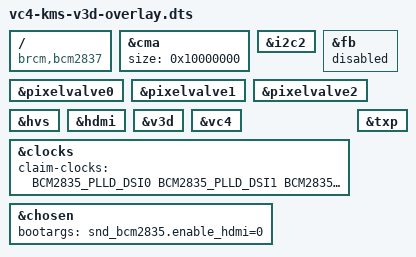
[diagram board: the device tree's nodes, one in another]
/*
 * vc4-kms-v3d-overlay.dts
 */

#include <dt-bindings/clock/bcm2835.h>

/*
 * cma.dts
 */

/dts-v1/;
/plugin/;

/ {
	compatible = "brcm,bcm2837";

	fragment@0 {
		target = <&cma>;
		frag0: __overlay__ {
			/*
			 * The default size when using this overlay is 256 MB
			 * and should be kept as is for backwards
			 * compatibility.
			 */
			size = <0x10000000>;
		};
	};

	fragment@1 {
		target = <&i2c2>;
		__overlay__  {
			status = "okay";
		};
	};

	fragment@2 {
		target = <&fb>;
		__overlay__  {
			status = "disabled";
		};
	};

	fragment@3 {
		target = <&pixelvalve0>;
		__overlay__  {
			status = "okay";
		};
	};

	fragment@4 {
		target = <&pixelvalve1>;
		__overlay__  {
			status = "okay";
		};
	};

	fragment@5 {
		target = <&pixelvalve2>;
		__overlay__  {
			status = "okay";
		};
	};

	fragment@6 {
		target = <&hvs>;
		__overlay__  {
			status = "okay";
		};
	};

	fragment@7 {
		target = <&hdmi>;
		__overlay__  {
			status = "okay";
		};
	};

	fragment@8 {
		target = <&v3d>;
		__overlay__  {
			status = "okay";
		};
	};

	fragment@9 {
		target = <&vc4>;
		__overlay__  {
			status = "okay";
		};
	};

	fragment@10 {
		target = <&clocks>;
		__overlay__  {
			claim-clocks = <
				BCM2835_PLLD_DSI0
				BCM2835_PLLD_DSI1
				BCM2835_PLLH_AUX
				BCM2835_PLLH_PIX
			>;
		};
	};

	fragment@11 {
		target = <&vec>;
		__dormant__  {
			status = "okay";
		};
	};

	fragment@12 {
		target = <&txp>;
		__overlay__  {
			status = "okay";
		};
	};

	fragment@13 {
		target = <&hdmi>;
		__dormant__  {
			dmas;
		};
	};

	fragment@14 {
		target = <&chosen>;
		__overlay__  {
			bootargs = "snd_bcm2835.enable_hdmi=0";
		};
	};

	__overrides__ {
		audio   = <0>,"!13";
		noaudio = <0>,"=13";
		composite = <0>, "=11";
		nohdmi = <0>, "-1-7";
		cma-512 = <&frag0>,"size:0=",<0x20000000>;
		cma-448 = <&frag0>,"size:0=",<0x1c000000>;
		cma-384 = <&frag0>,"size:0=",<0x18000000>;
		cma-320 = <&frag0>,"size:0=",<0x14000000>;
		cma-256 = <&frag0>,"size:0=",<0x10000000>;
		cma-192 = <&frag0>,"size:0=",<0xC000000>;
		cma-128 = <&frag0>,"size:0=",<0x8000000>;
		cma-96  = <&frag0>,"size:0=",<0x6000000>;
		cma-64  = <&frag0>,"size:0=",<0x4000000>;
		cma-size = <&frag0>,"size:0"; /* in bytes, 4MB aligned */
		cma-default = <0>,"-0";
	};
};
